# STM32F107xC register map
File version: 1.0
Registers are 32-bit, read-write, reset 0x0 unless marked. A register's access mark holds for its fields unless they carry their own. Offsets are from the block's base; [hi:lo] are bit positions; {n}, {i} and the like mark numbered series; 'fields as' and 'values as' point back to an identical list.

## RCC — Reset and Clock Control
Base 0x40021000
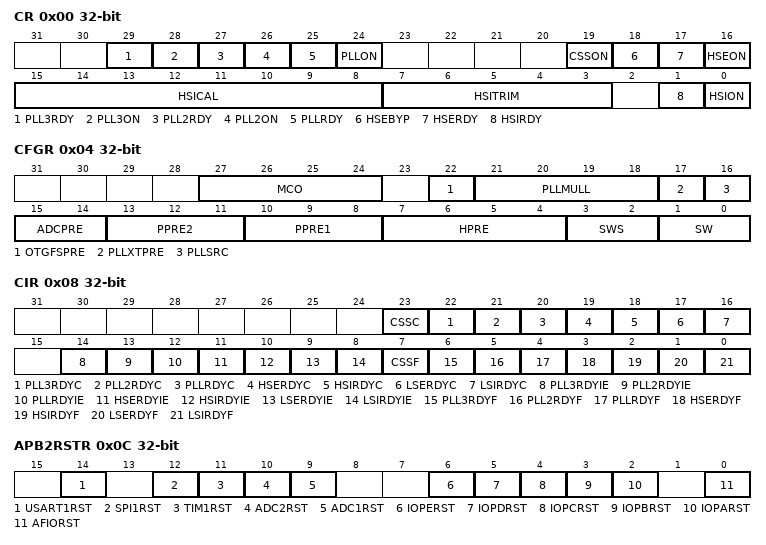
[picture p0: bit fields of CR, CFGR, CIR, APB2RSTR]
0x00 CR
  [29] PLL3RDY — PLL3 clock ready flag
  [28] PLL3ON — PLL3 enable
  [27] PLL2RDY — PLL2 clock ready flag
  [26] PLL2ON — PLL2 enable
  [25] PLLRDY — PLL clock ready flag
  [24] PLLON — PLL enable
  [19] CSSON — Clock Security System enable
  [18] HSEBYP — External High Speed clock Bypass
  [17] HSERDY — External High Speed clock ready flag
  [16] HSEON — External High Speed clock enable
  [15:8] HSICAL — Internal High Speed clock Calibration
  [7:3] HSITRIM — Internal High Speed clock trimming
  [1] HSIRDY — Internal High Speed clock ready flag
  [0] HSION — Internal High Speed clock enable
0x04 CFGR
  [27:24] MCO — MCO[3:0] bits (Microcontroller Clock Output)
  [22] OTGFSPRE — USB OTG FS prescaler
  [21:18] PLLMULL — PLLMUL[3:0] bits (PLL multiplication factor)
    {v}=MUL_{v+2} (PLL input clock*{v+2}) (v=2..7); 13=MUL_6_5 (PLL input clock*6)
  [17] PLLXTPRE — HSE divider for PLL entry
  [16] PLLSRC — PLL entry clock source
  [15:14] ADCPRE — ADCPRE[1:0] bits (ADC prescaler)
    0=DIV_2; 1=DIV_4; 2=DIV_6; 3=DIV_8
  [13:11] PPRE2 — PRE2[2:0] bits (APB2 prescaler)
    0=DIV_1 (HCLK not divided); 4=DIV_2 (HCLK divided by 2); 5=DIV_4 (HCLK divided by 4); 6=DIV_8 (HCLK divided by 8); 7=DIV_16 (HCLK divided by 16)
  [10:8] PPRE1 — PRE1[2:0] bits (APB1 prescaler)
    values as PPRE2
  [7:4] HPRE — HPRE[3:0] bits (AHB prescaler)
    0=DIV_1 (SYSCLK not divided); 8=DIV_2 (SYSCLK divided by 2); 9=DIV_4 (SYSCLK divided by 4); 10=DIV_8 (SYSCLK divided by 8); 11=DIV_16 (SYSCLK divided by 16); 12=DIV_64 (SYSCLK divided by 64); 13=DIV_128 (SYSCLK divided by 128); 14=DIV_256 (SYSCLK divided by 256); 15=DIV_512 (SYSCLK divided by 512)
  [3:2] SWS — SWS[1:0] bits (System Clock Switch Status)
    0=HSI (HSI used as system clock); 1=HSE (HSE used as system clock); 2=PLL (PLL used as system clock)
  [1:0] SW — SW[1:0] bits (System clock Switch)
    0=HSI (HSI selection as system clock); 1=HSE (HSE selection as system clock); 2=PLL (PLL selection as system clock)
0x08 CIR
  [23] CSSC — Clock Security System Interrupt Clear
  [22] PLL3RDYC — PLL3 Ready Interrupt Clear
  [21] PLL2RDYC — PLL2 Ready Interrupt Clear
  [20] PLLRDYC — PLL Ready Interrupt Clear
  [19] HSERDYC — HSE Ready Interrupt Clear
  [18] HSIRDYC — HSI Ready Interrupt Clear
  [17] LSERDYC — LSE Ready Interrupt Clear
  [16] LSIRDYC — LSI Ready Interrupt Clear
  [14] PLL3RDYIE — PLL3 Ready Interrupt Enable
  [13] PLL2RDYIE — PLL2 Ready Interrupt Enable
  [12] PLLRDYIE — PLL Ready Interrupt Enable
  [11] HSERDYIE — HSE Ready Interrupt Enable
  [10] HSIRDYIE — HSI Ready Interrupt Enable
  [9] LSERDYIE — LSE Ready Interrupt Enable
  [8] LSIRDYIE — LSI Ready Interrupt Enable
  [7] CSSF — Clock Security System Interrupt flag
  [6] PLL3RDYF — PLL3 Ready Interrupt flag
  [5] PLL2RDYF — PLL2 Ready Interrupt flag
  [4] PLLRDYF — PLL Ready Interrupt flag
  [3] HSERDYF — HSE Ready Interrupt flag
  [2] HSIRDYF — HSI Ready Interrupt flag
  [1] LSERDYF — LSE Ready Interrupt flag
  [0] LSIRDYF — LSI Ready Interrupt flag
0x0C APB2RSTR
  [14] USART1RST — USART1 reset
  [12] SPI1RST — SPI 1 reset
  [11] TIM1RST — TIM1 Timer reset
  [10] ADC2RST — ADC 2 interface reset
  [9] ADC1RST — ADC 1 interface reset
  [6] IOPERST — I/O port E reset
  [5] IOPDRST — I/O port D reset
  [4] IOPCRST — I/O port C reset
  [3] IOPBRST — I/O port B reset
  [2] IOPARST — I/O port A reset
  [0] AFIORST — Alternate Function I/O reset
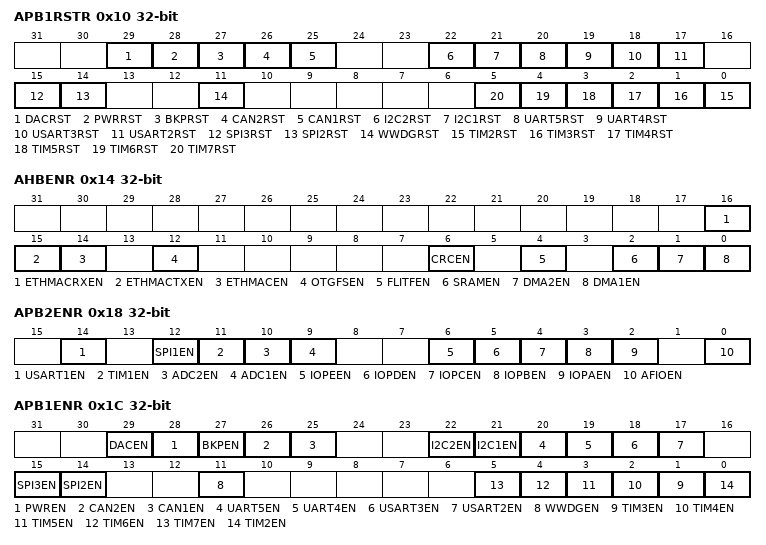
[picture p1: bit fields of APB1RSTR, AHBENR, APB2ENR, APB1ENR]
0x10 APB1RSTR
  [29] DACRST — DAC interface reset
  [28] PWRRST — Power interface reset
  [27] BKPRST — Backup interface reset
  [26] CAN2RST — CAN2 reset
  [25] CAN1RST — CAN1 reset
  [22] I2C2RST — I2C 2 reset
  [21] I2C1RST — I2C 1 reset
  [20] UART5RST — UART 5 reset
  [19] UART4RST — UART 4 reset
  [18] USART3RST — USART 3 reset
  [17] USART2RST — USART 2 reset
  [15] SPI3RST — SPI 3 reset
  [14] SPI2RST — SPI 2 reset
  [11] WWDGRST — Window Watchdog reset
  [n-2] TIM{n}RST (n=2..7) — Timer {n} reset
0x14 AHBENR
  [16] ETHMACRXEN — ETHERNET MAC Rx clock enable
  [15] ETHMACTXEN — ETHERNET MAC Tx clock enable
  [14] ETHMACEN — ETHERNET MAC clock enable
  [12] OTGFSEN — USB OTG FS clock enable
  [6] CRCEN — CRC clock enable
  [4] FLITFEN — FLITF clock enable
  [2] SRAMEN — SRAM interface clock enable
  [1] DMA2EN — DMA2 clock enable
  [0] DMA1EN — DMA1 clock enable
0x18 APB2ENR
  [14] USART1EN — USART1 clock enable
  [12] SPI1EN — SPI 1 clock enable
  [11] TIM1EN — TIM1 Timer clock enable
  [10] ADC2EN — ADC 2 interface clock enable
  [9] ADC1EN — ADC 1 interface clock enable
  [6] IOPEEN — I/O port E clock enable
  [5] IOPDEN — I/O port D clock enable
  [4] IOPCEN — I/O port C clock enable
  [3] IOPBEN — I/O port B clock enable
  [2] IOPAEN — I/O port A clock enable
  [0] AFIOEN — Alternate Function I/O clock enable
0x1C APB1ENR
  [29] DACEN — DAC interface clock enable
  [28] PWREN — Power interface clock enable
  [27] BKPEN — Backup interface clock enable
  [26] CAN2EN — CAN2 clock enable
  [25] CAN1EN — CAN1 clock enable
  [22] I2C2EN — I2C 2 clock enable
  [21] I2C1EN — I2C 1 clock enable
  [20] UART5EN — UART 5 clock enable
  [19] UART4EN — UART 4 clock enable
  [18] USART3EN — USART 3 clock enable
  [17] USART2EN — USART 2 clock enable
  [15] SPI3EN — SPI 3 clock enable
  [14] SPI2EN — SPI 2 clock enable
  [11] WWDGEN — Window Watchdog clock enable
  [n-2] TIM{n}EN (n=3..7) — Timer {n} clock enable
  [0] TIM2EN — Timer 2 clock enabled
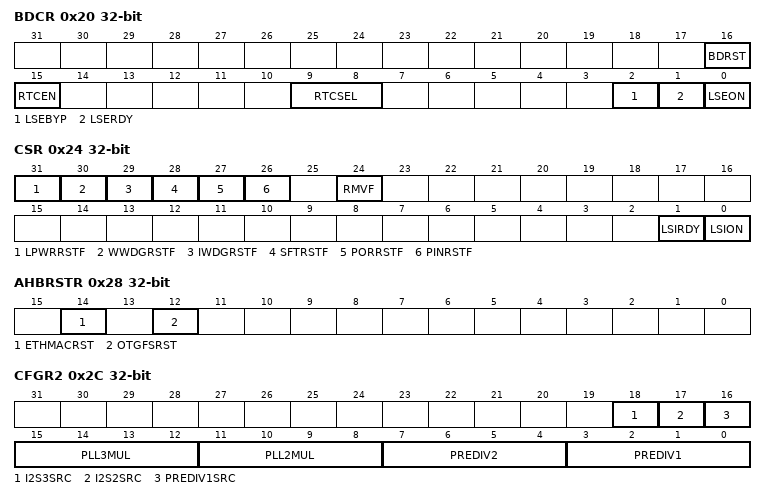
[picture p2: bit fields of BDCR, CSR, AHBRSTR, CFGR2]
0x20 BDCR
  [16] BDRST — Backup domain software reset
  [15] RTCEN — RTC clock enable
  [9:8] RTCSEL — RTCSEL[1:0] bits (RTC clock source selection)
    0=NONE (No clock used as RTC clock); 1=LSE (LSE oscillator clock used as RTC clock); 2=LSI (LSI oscillator clock used as RTC clock); 3=HSE_DIV128 (HSE oscillator clock divided by 128 used as RTC clock)
  [2] LSEBYP — External Low Speed oscillator Bypass
  [1] LSERDY — External Low Speed oscillator Ready
  [0] LSEON — External Low Speed oscillator enable
0x24 CSR
  [31] LPWRRSTF — Low-Power reset flag
  [30] WWDGRSTF — Window watchdog reset flag
  [29] IWDGRSTF — Independent Watchdog reset flag
  [28] SFTRSTF — Software Reset flag
  [27] PORRSTF — POR/PDR reset flag
  [26] PINRSTF — PIN reset flag
  [24] RMVF — Remove reset flag
  [1] LSIRDY — Internal Low Speed oscillator Ready
  [0] LSION — Internal Low Speed oscillator enable
0x28 AHBRSTR
  [14] ETHMACRST — ETHERNET MAC reset
  [12] OTGFSRST — USB OTG FS reset
0x2C CFGR2
  [18] I2S3SRC — I2S3 clock source
  [17] I2S2SRC — I2S2 entry clock source
  [16] PREDIV1SRC — PREDIV1 entry clock source
  [15:12] PLL3MUL — PLL3MUL[3:0] bits
    {v}=MUL_{v+2} (PLLI2S input clock * {v+2}) (v=6..12); 14=MUL_16 (PLLI2S input clock * 16); 15=MUL_20 (PLLI2S input clock * 20)
  [11:8] PLL2MUL — PLL2MUL[3:0] bits
    {v}=MUL_{v+2} (PLL2 input clock * {v+2}) (v=6..12); 14=MUL_16 (PLL2 input clock * 16); 15=MUL_20 (PLL2 input clock * 20)
  [7:4] PREDIV2 — PREDIV2[3:0] bits
    0=DIV_1 (PREDIV2 input clock not divided); {v}=DIV_{v+1} (PREDIV2 input clock divided by {v+1}) (v=1..15)
  [3:0] PREDIV1 — PREDIV1[3:0] bits
